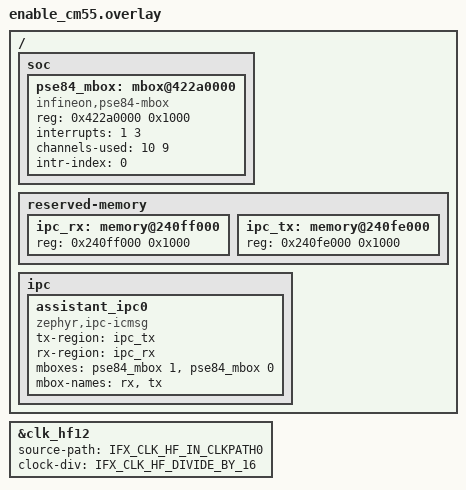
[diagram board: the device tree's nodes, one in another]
/*
 * M33 companion overlay: force CLK_HF12 to run at 25 MHz.
 *
 * The demo uses external 24 MHz oscillator via CLKPATH4 → CLK_HF12, which
 * feeds the MIPI-DSI D-PHY PLL reference. Zephyr's board DTS sets HF12 to
 * CLKPATH4 too, but the path_mux4 source defaults to no running clock →
 * HF12 = 0 Hz → D-PHY PLL never locks → cy_mipi_dsi_dphy_enable() waits
 * forever in its unbounded PHY_LOCK polling loop.
 *
 * Fix: route CLK_HF12 to CLKPATH0 (DPLL_LP0 = 400 MHz) with divide-by-16
 * to get 25 MHz — close enough to 24 MHz for the D-PHY PLL lock range.
 */

#include <zephyr/dt-bindings/clock/ifx_clock_source_common.h>

&clk_hf12 {
	source-path = <IFX_CLK_HF_IN_CLKPATH0>;
	clock-div = <IFX_CLK_HF_DIVIDE_BY_16>;
	status = "okay";
};

/*
 * IPC + MBOX nodes for the M33 side of the 'assistant' ipc_service
 * tunnel. TX/RX channels swapped relative to pse84_assistant's M55
 * overlay so the icmsg ring matches (M55 TX ch9 = M33 RX ch9; etc.).
 * NVIC IRQ 1 = m33syscpuss_interrupts_ipc_dpslp_0_IRQn (DeepSleep
 * table) per cy_device_headers_ns.h.
 */
/ {
	soc {
		pse84_mbox: mbox@422a0000 {
			compatible = "infineon,pse84-mbox";
			reg = <0x422a0000 0x1000>;
			interrupts = <1 3>;
			channels-used = <10 9>;
			intr-index = <0>;
			#mbox-cells = <1>;
			status = "okay";
		};
	};

	reserved-memory {
		#address-cells = <1>;
		#size-cells = <1>;

		ipc_rx: memory@240ff000 {
			reg = <0x240ff000 0x1000>;
		};
		ipc_tx: memory@240fe000 {
			reg = <0x240fe000 0x1000>;
		};
	};

	ipc {
		assistant_ipc0: assistant_ipc0 {
			compatible = "zephyr,ipc-icmsg";
			tx-region = <&ipc_tx>;
			rx-region = <&ipc_rx>;
			mboxes = <&pse84_mbox 1>, <&pse84_mbox 0>;
			mbox-names = "rx", "tx";
			status = "okay";
		};
	};
};
